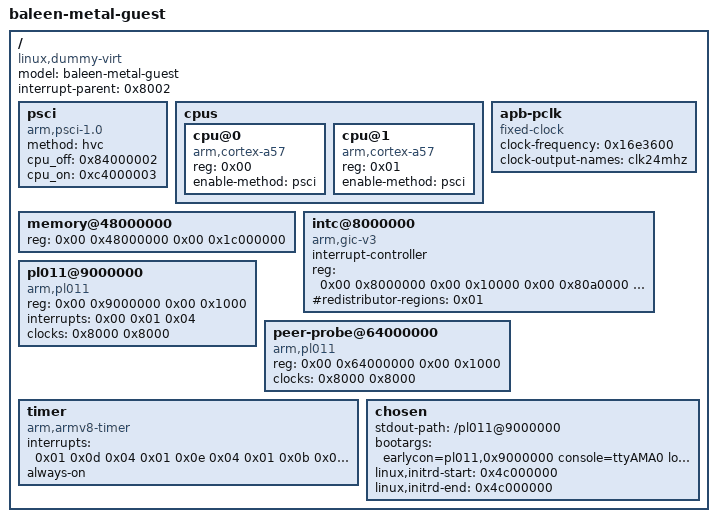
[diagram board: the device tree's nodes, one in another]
/dts-v1/;

/*
 * SPDX-License-Identifier: Apache-2.0 OR MIT
 * Copyright (c) 2026 Via Balaena
 *
 * M5 Arc 5e — the real-Linux capstone device tree.
 *
 * A MINIMAL device tree for a single Linux guest that "owns the machine" under hv-metal's EL2
 * (see docs/ARC-5-M5-GUEST-INTERFACE.md). Only the nodes the guest actually drives are present, so
 * Linux probes ONLY what hv-metal passes through in Stage-2 — no peripheral it can't reach.
 *
 * Derived from the QEMU `virt` (gic-version=3, virtualization=on) device tree, with three changes:
 *   1. psci `method` = "hvc"  (Linux's PSCI HVCs trap to hv-metal's Arc-5c handler; there is no EL3).
 *   2. /memory relocated to 0x4800_0000 (hv-metal owns the low 128 MiB; the guest owns the rest).
 *   3. /chosen carries our bootargs + the initramfs range (initrd-end patched by `cargo xtask
 *      qemu-linux` to start + the initramfs file size).
 *
 * The GICv3 / PL011 / timer reg + interrupt values are the REAL QEMU `virt` addresses, because the
 * guest drives the real hardware (hv-metal maps GICD 0x0800_0000 + GICR 0x080a_0000 + PL011
 * 0x0900_0000 through Stage-2 with HCR_EL2.IMO=0). Addresses here MUST match linux.rs's layout.
 */

/ {
	#address-cells = <0x02>;
	#size-cells = <0x02>;
	compatible = "linux,dummy-virt";
	model = "baleen-metal-guest";
	interrupt-parent = <0x8002>;

	psci {
		compatible = "arm,psci-1.0", "arm,psci-0.2", "arm,psci";
		method = "hvc";
		cpu_off = <0x84000002>;
		cpu_on = <0xc4000003>;
	};

	cpus {
		#address-cells = <0x01>;
		#size-cells = <0x00>;

		/* ⑱-4b-ii — TWO CPUs, and this is the SECOND content edit this file has ever had.
		   ③'s earned property was that taking a device AWAY never required editing the guest's
		   description; the first addition was ③-b2b-ii-d's peer-probe node, and this is the
		   second. It is not a weakening of that property so much as its other direction: a guest
		   cannot USE a CPU its machine description does not mention, so GIVING it one has to be
		   said here. Say "the DTS gained a probe, and then a second CPU"; do not say it is
		   untouched.

		   `reg` is the hwid Linux matches against `MPIDR_EL1 & MPIDR_HWID_BITMASK`, and
		   `linux.rs`'s `guest_mpidr` is the one derivation of it — pinned by a `const assert!`
		   for cpu 0 and, since this rung, reachable for cpu 1 only through the same function.
		   `enable-method` matches the form QEMU's own generated DTB uses, and the `psci` node
		   above already declared `cpu_on = <0xc4000003>` long before anything answered it.

		   MEASURED with this node present and `CPU_ON` still unimplemented: each guest calls the
		   FID exactly once (`x1=0x1`, `x2` = an address in its OWN RAM, `x3=0x0`), is told
		   NOT_SUPPORTED, prints `psci: failed to boot CPU1 (-95)` and continues to userspace with
		   `SMP: Total of 1 processors activated.` — which is why that string is a FORBIDDEN
		   marker now. */
		cpu@0 {
			device_type = "cpu";
			compatible = "arm,cortex-a57";
			reg = <0x00>;
			enable-method = "psci";
		};

		cpu@1 {
			device_type = "cpu";
			compatible = "arm,cortex-a57";
			reg = <0x01>;
			enable-method = "psci";
		};
	};

	/* This guest's RAM: 0x4800_0000 .. 0x6400_0000 (448 MiB) — half the 896 MiB window, since
	   ③-b2a split it with a peer domain. hv-metal owns 0x4000_0000..0x4800_0000. */
	memory@48000000 {
		device_type = "memory";
		// ③-b2a: 448 MiB, not 896 — the window is SPLIT and dom 2 owns the upper half
		// (0x64000000..0x80000000). Must match `stage2::LINUX_RAM_SPLIT`; the boot banner
		// prints both halves and `xtask::LINUX_MARKERS` asserts that line.
		reg = <0x00 0x48000000 0x00 0x1c000000>;
	};

	apb-pclk {
		compatible = "fixed-clock";
		#clock-cells = <0x00>;
		clock-frequency = <0x16e3600>;
		clock-output-names = "clk24mhz";
		phandle = <0x8000>;
	};

	/* GICv3: distributor @ 0x0800_0000 (64 KiB), redistributor @ 0x080a_0000. */
	intc@8000000 {
		compatible = "arm,gic-v3";
		#interrupt-cells = <0x03>;
		interrupt-controller;
		reg = <0x00 0x8000000 0x00 0x10000
		       0x00 0x80a0000 0x00 0xf60000>;
		#redistributor-regions = <0x01>;
		phandle = <0x8002>;
	};

	pl011@9000000 {
		compatible = "arm,pl011", "arm,primecell";
		reg = <0x00 0x9000000 0x00 0x1000>;
		interrupts = <0x00 0x01 0x04>;
		clocks = <0x8000 0x8000>;
		clock-names = "uartclk", "apb_pclk";
	};

	/*
	 * ③-b2b-ii-d — THE PEER PROBE, and the one node here that is not a device this guest has.
	 *
	 * It names an AMBA peripheral at the base of the OTHER guest's half of the RAM window, so the
	 * kernel's AMBA bus scan reads its identification registers during boot. Those reads are
	 * Stage-2 aborts to EL2 (this guest's image does not map the peer's memory), which is exactly
	 * the isolation property, asserted by a running guest attempting a real access rather than by
	 * a walk over descriptors. EL2 recognises them, checks that the SAME address resolves in the
	 * peer's live image and holds the peer's loaded kernel, skips the instruction, and the guest
	 * carries on: the identification read returns nothing that matches, so no driver binds and the
	 * device is dropped with -ENODEV.
	 *
	 * DECLARED COST, because ③ spent four rungs earning the opposite: this is an ADDITION to the
	 * guest's device tree. ③'s property — that taking a device away from a guest never required
	 * editing its description — is untouched; this node is not an accommodation of our emulation,
	 * it is the negative test's instrument, and it is the only thing here that exists to fail.
	 *
	 * `xtask` rewrites the address per guest (dom 1 probes 0x64000000, dom 2 probes 0x48000000).
	 */
	peer-probe@64000000 {
		compatible = "arm,pl011", "arm,primecell";
		reg = <0x00 0x64000000 0x00 0x1000>;
		clocks = <0x8000 0x8000>;
		clock-names = "uartclk", "apb_pclk";
	};

	timer {
		compatible = "arm,armv8-timer";
		interrupts = <0x01 0x0d 0x04
		              0x01 0x0e 0x04
		              0x01 0x0b 0x04
		              0x01 0x0a 0x04>;
		always-on;
	};

	chosen {
		stdout-path = "/pl011@9000000";
		bootargs = "earlycon=pl011,0x9000000 console=ttyAMA0 loglevel=8";
		/* initrd loaded at 0x4c00_0000 by `-device loader`; end = start + size, patched by xtask. */
		linux,initrd-start = <0x4c000000>;
		linux,initrd-end = <0x4c000000>;
	};
};
